# MSS_GIO register map
Vendor: Texas Instruments
Peripheral module from a debugger description file (folder radar).
Registers are 32-bit, read-write, no defined reset value unless marked. A register's access mark holds for its fields unless they carry their own. Offsets are as the file gives them; lines under a group give offsets from that group; [hi:lo] are bit positions; {n}, {i} and the like mark numbered series; 'fields as' and 'values as' point back to an identical list; <NAME> marks a mode.

## MSS_GIO
0x00 GIOGCR
  [0] RESET — GIO reset
0x08 GIOPWDN
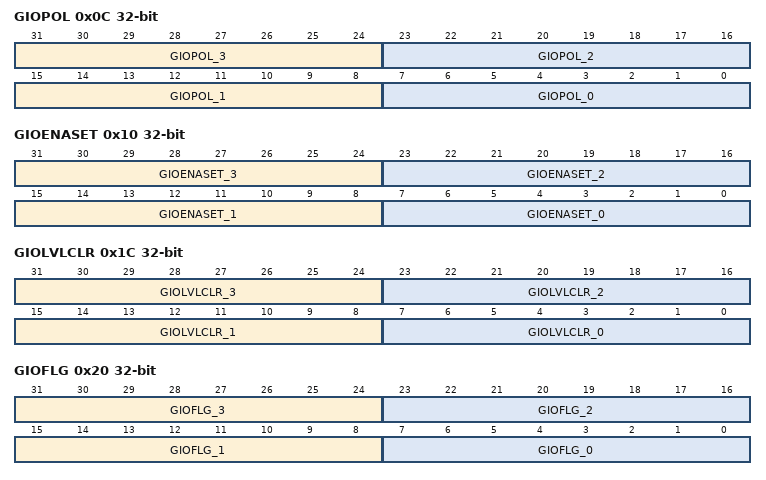
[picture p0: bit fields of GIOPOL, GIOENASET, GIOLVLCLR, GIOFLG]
0x0C GIOPOL
  [31:24] GIOPOL_3 — Interrupt polarity select for pins GIOD[7:0]
  [23:16] GIOPOL_2 — Interrupt polarity select for pins GIOC[7:0]
  [15:8] GIOPOL_1 — Interrupt polarity select for pins GIOB[7:0]
  [7:0] GIOPOL_0 — Interrupt polarity select for pins GIOA[7:0]
0x10 GIOENASET
  [31:24] GIOENASET_3 — Interrupt enable for pins GIOD [7:0]
  [23:16] GIOENASET_2 — Interrupt enable for pins GIOC [7:0]
  [15:8] GIOENASET_1 — Interrupt enable for pins GIOB [7:0]
  [7:0] GIOENASET_0 — Interrupt enable for pins GIOA [7:0]
0x14 GIOENACLR access not given
0x18 GIOLVL_SET access not given
0x1C GIOLVLCLR
  [31:24] GIOLVLCLR_3 — GIO low priority interrupt for pins GIOD[7:0]
  [23:16] GIOLVLCLR_2 — GIO low priority interrupt for pins GIOC[7:0]
  [15:8] GIOLVLCLR_1 — GIO low priority interrupt for pins GIOB[7:0]
  [7:0] GIOLVLCLR_0 — GIO low priority interrupt for pins GIOA[7:0]
0x20 GIOFLG
  [31:24] GIOFLG_3 — GIO flag for pins GIOD[7:0]
  [23:16] GIOFLG_2 — GIO flag for pins GIOC[7:0]
  [15:8] GIOFLG_1 — GIO flag for pins GIOB[7:0]
  [7:0] GIOFLG_0 — GIO flag for pins GIOA[7:0]
0x24 GIOOFFA
  [5:0] GIOOFFA — Index bits for currently pending high-priority interrupt Register A
0x28 GIOOFFB
  [5:0] GIOOFFB — Index bits for currently pending high-priority interrupt Register B
0x2C GIOEMUA
  [5:0] GIOEMUA — GIO emulation register A
0x30 GIOEMUB
  [5:0] GIOEMUB — GIO emulation register B
0x34 GIODIR0A access not given
0x38 GIODIN0A access not given
0x3C GIODOUTA
  [7:0] GIODOUTA — GIO data output for pins in port A
0x40 GIOSETA access not given
0x44 GIOCLRA access not given
0x48 GIOPDRA
  [7:0] GIOPDRA — GIO open drain for port A
0x4C GIOPULDISA
  [7:0] GIOPULDISA — GIO pull disable for port A
0x50 GIOPSLA
  [7:0] GIOPSLA — GIO pull select for port A
0x54 GIODIR0B access not given
0x58 GIODIN0B access not given
0x5C GIODOUTB
  [7:0] GIODOUTB — GIO data output for pins in port B
0x60 GIOSETB access not given
0x64 GIOCLRB access not given
0x68 GIOPDRB
  [7:0] GIOPDRB — GIO open drain for port B
0x6C GIOPULDISB
  [7:0] GIOPULDISB — GIO pull disable for port B
0x70 GIOPSLB
  [7:0] GIOPSLB — GIO pull select for port B
0x74 GIODIR0C access not given
0x78 GIODIN0C access not given
0x7C GIODOUTC
  [7:0] GIODOUTC — GIO data output for pins in port C
0x80 GIOSETC access not given
0x84 GIOCLRC access not given
0x88 GIOPDRC
  [7:0] GIOPDRC — GIO open drain for port C
0x8C GIOPULDISC
  [7:0] GIOPULDISC — GIO pull disable for port C
0x90 GIOPSLC
  [7:0] GIOPSLC — GIO pull select for port C
0x94 GIODIR0D access not given
0x98 GIODIN0D access not given
0x9C GIODOUTD
  [7:0] GIODOUTD — GIO data output for pins in port D
0xA0 GIOSETD access not given
0xA4 GIOCLRD access not given
0xA8 GIOPDRD
  [7:0] GIOPDRD — GIO open drain for port D
0xAC GIOPULDISD
  [7:0] GIOPULDISD — GIO pull disable for port D
0xB0 GIOPSLD
  [7:0] GIOPSLD — GIO pull select for port D
